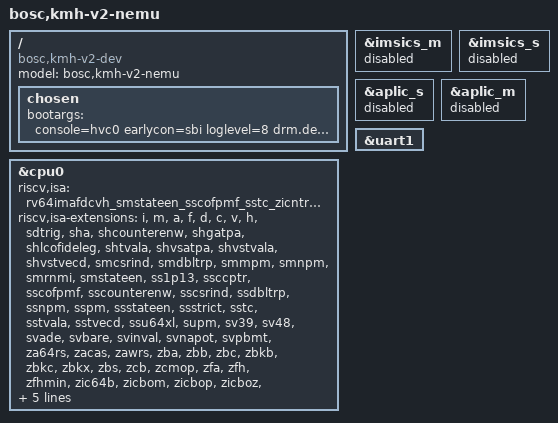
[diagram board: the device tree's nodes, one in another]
// SPDX-License-Identifier: (GPL-2.0 OR MIT)
/* Copyright (c) 2024-2025 BOSC */

/dts-v1/;
#include "kmh-v2.dtsi"

/ {
	#address-cells = <2>;
	#size-cells = <2>;
	compatible = "bosc,kmh-v2-dev";
	model = "bosc,kmh-v2-nemu";

	chosen {
		bootargs = "console=hvc0 earlycon=sbi loglevel=8 drm.debug=0x2";
	};
};

&cpu0 {
	riscv,isa = "rv64imafdcvh_smstateen_sscofpmf_sstc_zicntr_zihpm_zicboz_zicbom_svpbmt_sdtrig_smcsrind_sscsrind_svade";
	riscv,isa-extensions = "i", "m", "a", "f", "d", "c", "v", "h", "sdtrig", "sha", "shcounterenw", "shgatpa", "shlcofideleg", "shtvala", "shvsatpa", "shvstvala", "shvstvecd", "smcsrind", "smdbltrp", "smmpm", "smnpm", "smrnmi", "smstateen", "ss1p13", "ssccptr", "sscofpmf", "sscounterenw", "sscsrind", "ssdbltrp", "ssnpm", "sspm", "ssstateen", "ssstrict", "sstc", "sstvala", "sstvecd", "ssu64xl", "supm", "sv39", "sv48", "svade", "svbare", "svinval", "svnapot", "svpbmt", "za64rs", "zacas", "zawrs", "zba", "zbb", "zbc", "zbkb", "zbkc", "zbkx", "zbs", "zcb", "zcmop", "zfa", "zfh", "zfhmin", "zic64b", "zicbom", "zicbop", "zicboz", "ziccamoa", "ziccif", "zicclsm", "ziccrse", "zicntr", "zicond", "zicsr", "zifencei", "zihintntl", "zihintpause", "zihpm", "zimop", "zkn", "zknd", "zkne", "zknh", "zksed", "zksh", "zkt", "zvbb", "zvfh", "zvfhmin", "zvkt", "zvl128b", "zvl32b", "zvl64b";
	status = "okay";
};

&imsics_m {
	status = "disabled";
};
&imsics_s {
	status = "disabled";
};
&aplic_s {
	status = "disabled";
};
&aplic_m {
	status = "disabled";
};
&uart1 {
	status = "okay";
};
